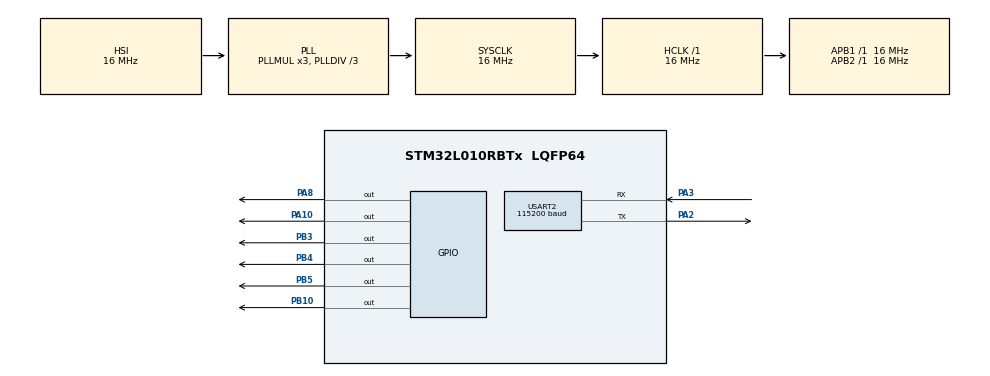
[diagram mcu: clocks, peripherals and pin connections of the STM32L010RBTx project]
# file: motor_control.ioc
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Mcu.Family=STM32L0
Mcu.Name=STM32L010RBTx
Mcu.Package=LQFP64
NVIC.TIM21_IRQn=true\:1\:0\:true\:false\:true\:true\:true\:true
NVIC.TIM22_IRQn=true\:1\:0\:true\:false\:true\:true\:true\:true
NVIC.USART2_IRQn=true\:0\:0\:true\:false\:true\:true\:true\:true
PA10.GPIO_ModeDefaultOutputPP=GPIO_MODE_OUTPUT_OD
PA10.GPIO_PuPd=GPIO_NOPULL
PA10.Signal=GPIO_Output
PA2.Mode=Asynchronous
PA2.Signal=USART2_TX
PA3.Mode=Asynchronous
PA3.Signal=USART2_RX
PA8.GPIO_ModeDefaultOutputPP=GPIO_MODE_OUTPUT_OD
PA8.GPIO_PuPd=GPIO_NOPULL
PA8.Signal=GPIO_Output
PB10.GPIO_ModeDefaultOutputPP=GPIO_MODE_OUTPUT_OD
PB10.GPIO_PuPd=GPIO_NOPULL
PB10.Signal=GPIO_Output
PB3.GPIO_ModeDefaultOutputPP=GPIO_MODE_OUTPUT_OD
PB3.GPIO_PuPd=GPIO_NOPULL
PB3.Signal=GPIO_Output
PB4.GPIO_ModeDefaultOutputPP=GPIO_MODE_OUTPUT_OD
PB4.GPIO_PuPd=GPIO_NOPULL
PB4.Signal=GPIO_Output
PB5.GPIO_ModeDefaultOutputPP=GPIO_MODE_OUTPUT_OD
PB5.GPIO_PuPd=GPIO_NOPULL
PB5.Signal=GPIO_Output
PH0-OSC_IN.Mode=HSE-External-Oscillator
PH0-OSC_IN.Signal=RCC_OSC_IN
PH1-OSC_OUT.Mode=HSE-External-Oscillator
PH1-OSC_OUT.Signal=RCC_OSC_OUT
ProjectManager.HeapSize=0x200
ProjectManager.StackSize=0x400
ProjectManager.TargetToolchain=STM32CubeIDE
RCC.AHBFreq_Value=16000000
RCC.APB1Freq_Value=16000000
RCC.APB1TimFreq_Value=16000000
RCC.APB2Freq_Value=16000000
RCC.APB2TimFreq_Value=16000000
RCC.HCLKFreq_Value=16000000
RCC.HSE_VALUE=8000000
RCC.HSI16_VALUE=16000000
RCC.HSI_VALUE=16000000
RCC.LSE_VALUE=32768
RCC.MSI_VALUE=2097000
RCC.PLLDIV=RCC_PLLDIV_3
RCC.SYSCLKFreq_VALUE=16000000
RCC.SYSCLKSource=RCC_SYSCLKSOURCE_PLLCLK
RCC.VCOOutputFreq_Value=48000000
TIM21.Period=60592
TIM21.Prescaler=9
TIM21.TIM_MasterOutputTrigger=TIM_TRGO_RESET
USART2.BaudRate=115200
USART2.OverrunDisableParam=ADVFEATURE_OVERRUN_ENABLE
USART2.VirtualMode-Asynchronous=VM_ASYNC
VP_TIM21_VS_ClockSourceINT.Mode=Internal
VP_TIM22_VS_ClockSourceINT.Mode=Internal
board=custom

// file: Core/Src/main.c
/* USER CODE BEGIN Header */
/**
  ******************************************************************************
  * @file           : main.c
  * @brief          : Main program body
  ******************************************************************************
  * @attention
  *
  * Copyright (c) 2025 STMicroelectronics.
  * All rights reserved.
  *
  * This software is licensed under terms that can be found in the LICENSE file
  * in the root directory of this software component.
  * If no LICENSE file comes with this software, it is provided AS-IS.
  *
  ******************************************************************************
  */
/* USER CODE END Header */
#include "main.h"

/* USER CODE BEGIN Includes */
#include "system_state.h"
#include "uart_handler.h"
#include "motor_controls.h"

/* USER CODE END Includes */

TIM_HandleTypeDef htim21;
TIM_HandleTypeDef htim22;

UART_HandleTypeDef huart2;

void SystemClock_Config(void);
static void MX_GPIO_Init(void);
static void MX_TIM21_Init(void);
static void MX_TIM22_Init(void);
static void MX_USART2_UART_Init(void);

int main(void)
{

  /* MCU Configuration--------------------------------------------------------*/

  /* Reset of all peripherals, Initializes the Flash interface and the Systick. */
  HAL_Init();

  /* Configure the system clock */
  SystemClock_Config();

  /* Initialize all configured peripherals */
  MX_GPIO_Init();
  MX_TIM21_Init();
  MX_TIM22_Init();
  MX_USART2_UART_Init();
  /* USER CODE BEGIN 2 */
  HAL_UART_Transmit(&huart2, (uint8_t *)"00", 2, 100);
  UART_StartReceiving();
  // HAL_TIM_Base_Start_IT(&htim21);
  /* USER CODE END 2 */

  /* Infinite loop */
  while (1)
  {

  }
}

void SystemClock_Config(void)
{
  RCC_OscInitTypeDef RCC_OscInitStruct = {0};
  RCC_ClkInitTypeDef RCC_ClkInitStruct = {0};
  RCC_PeriphCLKInitTypeDef PeriphClkInit = {0};

  /** Configure the main internal regulator output voltage
  */
  __HAL_PWR_VOLTAGESCALING_CONFIG(PWR_REGULATOR_VOLTAGE_SCALE1);

  /** Initializes the RCC Oscillators according to the specified parameters
  * in the RCC_OscInitTypeDef structure.
  */
  RCC_OscInitStruct.OscillatorType = RCC_OSCILLATORTYPE_HSI;
  RCC_OscInitStruct.HSIState = RCC_HSI_ON;
  RCC_OscInitStruct.HSICalibrationValue = RCC_HSICALIBRATION_DEFAULT;
  RCC_OscInitStruct.PLL.PLLState = RCC_PLL_ON;
  RCC_OscInitStruct.PLL.PLLSource = RCC_PLLSOURCE_HSI;
  RCC_OscInitStruct.PLL.PLLMUL = RCC_PLLMUL_3;
  RCC_OscInitStruct.PLL.PLLDIV = RCC_PLLDIV_3;
  if (HAL_RCC_OscConfig(&RCC_OscInitStruct) != HAL_OK)
  {
    Error_Handler();
  }

  /** Initializes the CPU, AHB and APB buses clocks
  */
  RCC_ClkInitStruct.ClockType = RCC_CLOCKTYPE_HCLK|RCC_CLOCKTYPE_SYSCLK
                              |RCC_CLOCKTYPE_PCLK1|RCC_CLOCKTYPE_PCLK2;
  RCC_ClkInitStruct.SYSCLKSource = RCC_SYSCLKSOURCE_PLLCLK;
  RCC_ClkInitStruct.AHBCLKDivider = RCC_SYSCLK_DIV1;
  RCC_ClkInitStruct.APB1CLKDivider = RCC_HCLK_DIV1;
  RCC_ClkInitStruct.APB2CLKDivider = RCC_HCLK_DIV1;

  if (HAL_RCC_ClockConfig(&RCC_ClkInitStruct, FLASH_LATENCY_0) != HAL_OK)
  {
    Error_Handler();
  }
  PeriphClkInit.PeriphClockSelection = RCC_PERIPHCLK_USART2;
  PeriphClkInit.Usart2ClockSelection = RCC_USART2CLKSOURCE_PCLK1;
  if (HAL_RCCEx_PeriphCLKConfig(&PeriphClkInit) != HAL_OK)
  {
    Error_Handler();
  }
}

static void MX_TIM21_Init(void)
{

  TIM_ClockConfigTypeDef sClockSourceConfig = {0};
  TIM_MasterConfigTypeDef sMasterConfig = {0};

  htim21.Instance = TIM21;
  htim21.Init.Prescaler = 9;
  htim21.Init.CounterMode = TIM_COUNTERMODE_UP;
  htim21.Init.Period = 5000;
  htim21.Init.ClockDivision = TIM_CLOCKDIVISION_DIV1;
  htim21.Init.AutoReloadPreload = TIM_AUTORELOAD_PRELOAD_DISABLE;
  if (HAL_TIM_Base_Init(&htim21) != HAL_OK)
  {
    Error_Handler();
  }
  sClockSourceConfig.ClockSource = TIM_CLOCKSOURCE_INTERNAL;
  if (HAL_TIM_ConfigClockSource(&htim21, &sClockSourceConfig) != HAL_OK)
  {
    Error_Handler();
  }
  sMasterConfig.MasterOutputTrigger = TIM_TRGO_RESET;
  sMasterConfig.MasterSlaveMode = TIM_MASTERSLAVEMODE_DISABLE;
  if (HAL_TIMEx_MasterConfigSynchronization(&htim21, &sMasterConfig) != HAL_OK)
  {
    Error_Handler();
  }

}

static void MX_TIM22_Init(void)
{

  TIM_ClockConfigTypeDef sClockSourceConfig = {0};
  TIM_MasterConfigTypeDef sMasterConfig = {0};

  htim22.Instance = TIM22;
  htim22.Init.Prescaler = 0;
  htim22.Init.CounterMode = TIM_COUNTERMODE_UP;
  htim22.Init.Period = 65535;
  htim22.Init.ClockDivision = TIM_CLOCKDIVISION_DIV1;
  htim22.Init.AutoReloadPreload = TIM_AUTORELOAD_PRELOAD_DISABLE;
  if (HAL_TIM_Base_Init(&htim22) != HAL_OK)
  {
    Error_Handler();
  }
  sClockSourceConfig.ClockSource = TIM_CLOCKSOURCE_INTERNAL;
  if (HAL_TIM_ConfigClockSource(&htim22, &sClockSourceConfig) != HAL_OK)
  {
    Error_Handler();
  }
  sMasterConfig.MasterOutputTrigger = TIM_TRGO_RESET;
  sMasterConfig.MasterSlaveMode = TIM_MASTERSLAVEMODE_DISABLE;
  if (HAL_TIMEx_MasterConfigSynchronization(&htim22, &sMasterConfig) != HAL_OK)
  {
    Error_Handler();
  }

}

static void MX_USART2_UART_Init(void)
{

  huart2.Instance = USART2;
  huart2.Init.BaudRate = 115200;
  huart2.Init.WordLength = UART_WORDLENGTH_8B;
  huart2.Init.StopBits = UART_STOPBITS_1;
  huart2.Init.Parity = UART_PARITY_NONE;
  huart2.Init.Mode = UART_MODE_TX_RX;
  huart2.Init.HwFlowCtl = UART_HWCONTROL_NONE;
  huart2.Init.OverSampling = UART_OVERSAMPLING_16;
  huart2.Init.OneBitSampling = UART_ONE_BIT_SAMPLE_DISABLE;
  huart2.AdvancedInit.AdvFeatureInit = UART_ADVFEATURE_NO_INIT;
  if (HAL_UART_Init(&huart2) != HAL_OK)
  {
    Error_Handler();
  }

}

static void MX_GPIO_Init(void)
{
  GPIO_InitTypeDef GPIO_InitStruct = {0};

  /* GPIO Ports Clock Enable */
  __HAL_RCC_GPIOH_CLK_ENABLE();
  __HAL_RCC_GPIOA_CLK_ENABLE();
  __HAL_RCC_GPIOB_CLK_ENABLE();

  /*Configure GPIO pin Output Level */
  HAL_GPIO_WritePin(GPIOB, GPIO_PIN_10|GPIO_PIN_3|GPIO_PIN_4|GPIO_PIN_5, GPIO_PIN_RESET);

  /*Configure GPIO pin Output Level */
  HAL_GPIO_WritePin(GPIOA, GPIO_PIN_8|GPIO_PIN_10, GPIO_PIN_RESET);

  /*Configure GPIO pins : PB10 PB3 PB4 PB5 */
  GPIO_InitStruct.Pin = GPIO_PIN_10|GPIO_PIN_3|GPIO_PIN_4|GPIO_PIN_5;
  GPIO_InitStruct.Mode = GPIO_MODE_OUTPUT_OD;
  GPIO_InitStruct.Pull = GPIO_NOPULL;
  GPIO_InitStruct.Speed = GPIO_SPEED_FREQ_LOW;
  HAL_GPIO_Init(GPIOB, &GPIO_InitStruct);

  /*Configure GPIO pins : PA8 PA10 */
  GPIO_InitStruct.Pin = GPIO_PIN_8|GPIO_PIN_10;
  GPIO_InitStruct.Mode = GPIO_MODE_OUTPUT_OD;
  GPIO_InitStruct.Pull = GPIO_NOPULL;
  GPIO_InitStruct.Speed = GPIO_SPEED_FREQ_LOW;
  HAL_GPIO_Init(GPIOA, &GPIO_InitStruct);

}

void Error_Handler(void)
{
  __disable_irq();
  while (1)
  {
  }
}
